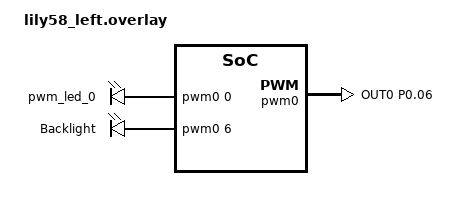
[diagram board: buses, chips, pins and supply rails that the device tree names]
&pinctrl {
    // Other pinctrl definitions for other hardware
    pwm0_default: pwm0_default {
        group1 {
            psels = <NRF_PSEL(PWM_OUT0, 0, 06)>;
        };
    };
    pwm0_sleep: pwm0_sleep {
        group1 {
            psels = <NRF_PSEL(PWM_OUT0, 0, 06)>;
            low-power-enable;
        };
    };
};

&pwm0 {
    status = "okay";
    pinctrl-0 = <&pwm0_default>;
    pinctrl-1 = <&pwm0_sleep>;
    pinctrl-names = "default", "sleep";
};

&pwmleds {
    compatible = "pwm-leds";

    backlight_pwm: backlight_pwm {
        pwms = <&pwm0 6 PWM_MSEC(1) PWM_POLARITY_NORMAL>; // P0.06 è il canale 6 su PWM0
        label = "Backlight";
    };
};

/ {
    backlight: pwmleds {
        compatible = "pwm-leds";
        pwm_led_0 {
            pwms = <&pwm0 0 PWM_MSEC(10) PWM_POLARITY_NORMAL>;
        };
    };

    chosen {
        zmk,backlight = &backlight;
    };
};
